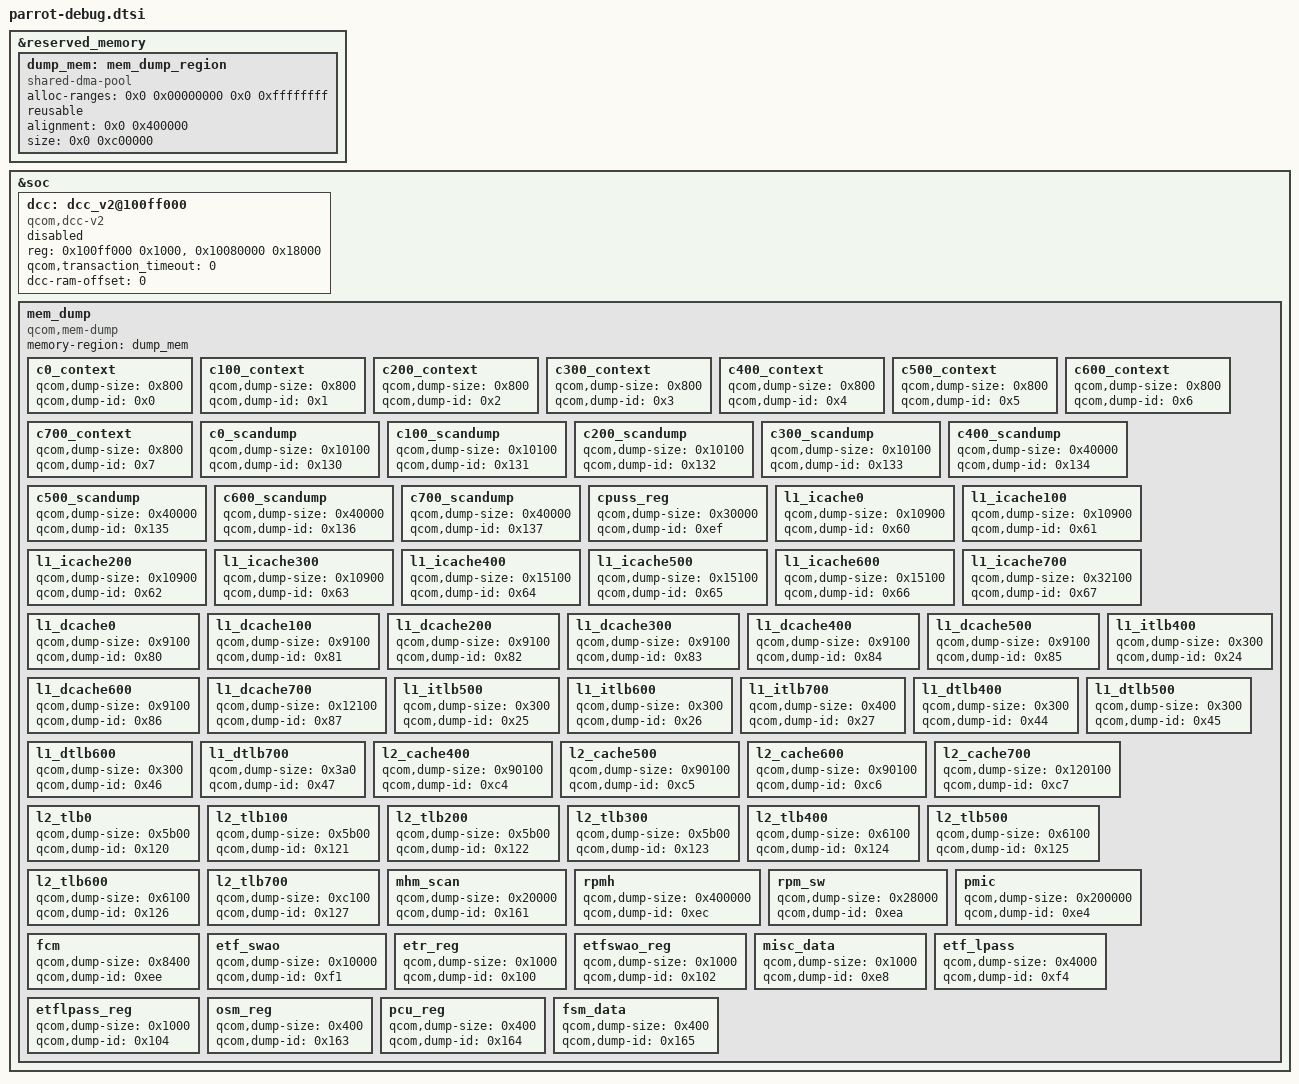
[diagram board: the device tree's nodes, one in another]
#include <dt-bindings/soc/qcom,dcc_v2.h>

&reserved_memory {
	#address-cells = <2>;
	#size-cells = <2>;
	ranges;

	dump_mem: mem_dump_region {
		compatible = "shared-dma-pool";
		alloc-ranges = <0x0 0x00000000 0x0 0xffffffff>;
		reusable;
		alignment = <0x0 0x400000>;
		size = <0x0 0xc00000>;
	};
};

&soc {
	dcc: dcc_v2@100ff000 {
		compatible = "qcom,dcc-v2";
		reg = <0x100ff000 0x1000>,
		      <0x10080000 0x18000>;

		qcom,transaction_timeout = <0>;

		reg-names = "dcc-base", "dcc-ram-base";
		dcc-ram-offset = <0>;
		status = "disabled";
	};

	mem_dump {
		compatible = "qcom,mem-dump";
		memory-region = <&dump_mem>;

		c0_context {
			qcom,dump-size = <0x800>;
			qcom,dump-id = <0x0>;
		};

		c100_context {
			qcom,dump-size = <0x800>;
			qcom,dump-id = <0x1>;
		};

		c200_context {
			qcom,dump-size = <0x800>;
			qcom,dump-id = <0x2>;
		};

		c300_context {
			qcom,dump-size = <0x800>;
			qcom,dump-id = <0x3>;
		};

		c400_context {
			qcom,dump-size = <0x800>;
			qcom,dump-id = <0x4>;
		};

		c500_context {
			qcom,dump-size = <0x800>;
			qcom,dump-id = <0x5>;
		};

		c600_context {
			qcom,dump-size = <0x800>;
			qcom,dump-id = <0x6>;
		};

		c700_context {
			qcom,dump-size = <0x800>;
			qcom,dump-id = <0x7>;
		};

		c0_scandump {
			qcom,dump-size = <0x10100>;
			qcom,dump-id = <0x130>;
		};

		c100_scandump {
			qcom,dump-size = <0x10100>;
			qcom,dump-id = <0x131>;
		};

		c200_scandump {
			qcom,dump-size = <0x10100>;
			qcom,dump-id = <0x132>;
		};

		c300_scandump {
			qcom,dump-size = <0x10100>;
			qcom,dump-id = <0x133>;
		};

		c400_scandump {
			qcom,dump-size = <0x40000>;
			qcom,dump-id = <0x134>;
		};

		c500_scandump {
			qcom,dump-size = <0x40000>;
			qcom,dump-id = <0x135>;
		};

		c600_scandump {
			qcom,dump-size = <0x40000>;
			qcom,dump-id = <0x136>;
		};

		c700_scandump {
			qcom,dump-size = <0x40000>;
			qcom,dump-id = <0x137>;
		};

		cpuss_reg {
			qcom,dump-size = <0x30000>;
			qcom,dump-id = <0xef>;
		};

		l1_icache0 {
			qcom,dump-size = <0x10900>;
			qcom,dump-id = <0x60>;
		};

		l1_icache100 {
			qcom,dump-size = <0x10900>;
			qcom,dump-id = <0x61>;
		};

		l1_icache200 {
			qcom,dump-size = <0x10900>;
			qcom,dump-id = <0x62>;
		};

		l1_icache300 {
			qcom,dump-size = <0x10900>;
			qcom,dump-id = <0x63>;
		};

		l1_icache400 {
			qcom,dump-size = <0x15100>;
			qcom,dump-id = <0x64>;
		};

		l1_icache500 {
			qcom,dump-size = <0x15100>;
			qcom,dump-id = <0x65>;
		};

		l1_icache600 {
			qcom,dump-size = <0x15100>;
			qcom,dump-id = <0x66>;
		};

		l1_icache700 {
			qcom,dump-size = <0x32100>;
			qcom,dump-id = <0x67>;
		};

		l1_dcache0 {
			qcom,dump-size = <0x9100>;
			qcom,dump-id = <0x80>;
		};

		l1_dcache100 {
			qcom,dump-size = <0x9100>;
			qcom,dump-id = <0x81>;
		};

		l1_dcache200 {
			qcom,dump-size = <0x9100>;
			qcom,dump-id = <0x82>;
		};

		l1_dcache300 {
			qcom,dump-size = <0x9100>;
			qcom,dump-id = <0x83>;
		};

		l1_dcache400 {
			qcom,dump-size = <0x9100>;
			qcom,dump-id = <0x84>;
		};

		l1_dcache500 {
			qcom,dump-size = <0x9100>;
			qcom,dump-id = <0x85>;
		};

		l1_dcache600 {
			qcom,dump-size = <0x9100>;
			qcom,dump-id = <0x86>;
		};

		l1_dcache700 {
			qcom,dump-size = <0x12100>;
			qcom,dump-id = <0x87>;
		};

		l1_itlb400 {
			qcom,dump-size = <0x300>;
			qcom,dump-id = <0x24>;
		};

		l1_itlb500 {
			qcom,dump-size = <0x300>;
			qcom,dump-id = <0x25>;
		};

		l1_itlb600 {
			qcom,dump-size = <0x300>;
			qcom,dump-id = <0x26>;
		};

		l1_itlb700 {
			qcom,dump-size = <0x400>;
			qcom,dump-id = <0x27>;
		};

		l1_dtlb400 {
			qcom,dump-size = <0x300>;
			qcom,dump-id = <0x44>;
		};

		l1_dtlb500 {
			qcom,dump-size = <0x300>;
			qcom,dump-id = <0x45>;
		};

		l1_dtlb600 {
			qcom,dump-size = <0x300>;
			qcom,dump-id = <0x46>;
		};

		l1_dtlb700 {
			qcom,dump-size = <0x3a0>;
			qcom,dump-id = <0x47>;
		};

		l2_cache400 {
			qcom,dump-size = <0x90100>;
			qcom,dump-id = <0xc4>;
		};

		l2_cache500 {
			qcom,dump-size = <0x90100>;
			qcom,dump-id = <0xc5>;
		};

		l2_cache600 {
			qcom,dump-size = <0x90100>;
			qcom,dump-id = <0xc6>;
		};

		l2_cache700 {
			qcom,dump-size = <0x120100>;
			qcom,dump-id = <0xc7>;
		};

		l2_tlb0 {
			qcom,dump-size = <0x5b00>;
			qcom,dump-id = <0x120>;
		};

		l2_tlb100 {
			qcom,dump-size = <0x5b00>;
			qcom,dump-id = <0x121>;
		};

		l2_tlb200 {
			qcom,dump-size = <0x5b00>;
			qcom,dump-id = <0x122>;
		};

		l2_tlb300 {
			qcom,dump-size = <0x5b00>;
			qcom,dump-id = <0x123>;
		};

		l2_tlb400 {
			qcom,dump-size = <0x6100>;
			qcom,dump-id = <0x124>;
		};

		l2_tlb500 {
			qcom,dump-size = <0x6100>;
			qcom,dump-id = <0x125>;
		};

		l2_tlb600 {
			qcom,dump-size = <0x6100>;
			qcom,dump-id = <0x126>;
		};

		l2_tlb700 {
			qcom,dump-size = <0xc100>;
			qcom,dump-id = <0x127>;
		};

		mhm_scan {
			qcom,dump-size = <0x20000>;
			qcom,dump-id = <0x161>;
		};

		rpmh {
			qcom,dump-size = <0x400000>;
			qcom,dump-id = <0xec>;
		};

		rpm_sw {
			qcom,dump-size = <0x28000>;
			qcom,dump-id = <0xea>;
		};

		pmic {
			qcom,dump-size = <0x200000>;
			qcom,dump-id = <0xe4>;
		};

		fcm {
			qcom,dump-size = <0x8400>;
			qcom,dump-id = <0xee>;
		};

		etf_swao {
			qcom,dump-size = <0x10000>;
			qcom,dump-id = <0xf1>;
		};

		etr_reg {
			qcom,dump-size = <0x1000>;
			qcom,dump-id = <0x100>;
		};

		etfswao_reg {
			qcom,dump-size = <0x1000>;
			qcom,dump-id = <0x102>;
		};

		misc_data {
			qcom,dump-size = <0x1000>;
			qcom,dump-id = <0xe8>;
		};

		etf_lpass {
			qcom,dump-size = <0x4000>;
			qcom,dump-id = <0xf4>;
		};

		etflpass_reg {
			qcom,dump-size = <0x1000>;
			qcom,dump-id = <0x104>;
		};

		osm_reg {
			qcom,dump-size = <0x400>;
			qcom,dump-id = <0x163>;
		};

		pcu_reg {
			qcom,dump-size = <0x400>;
			qcom,dump-id = <0x164>;
		};

		fsm_data {
			qcom,dump-size = <0x400>;
			qcom,dump-id = <0x165>;
		};
	};
};
